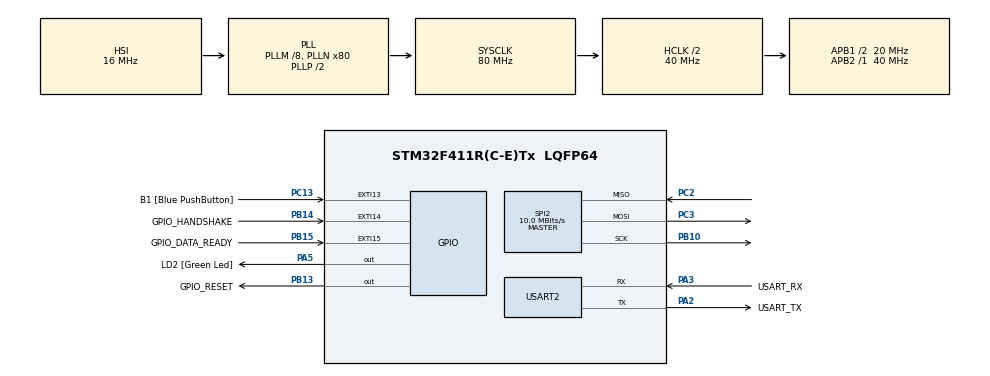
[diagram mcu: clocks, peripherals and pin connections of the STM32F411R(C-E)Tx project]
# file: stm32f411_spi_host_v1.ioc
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Dma.Request0=SPI2_RX
Dma.Request1=SPI2_TX
Dma.SPI2_RX.0.Direction=DMA_PERIPH_TO_MEMORY
Dma.SPI2_RX.0.FIFOMode=DMA_FIFOMODE_DISABLE
Dma.SPI2_RX.0.Instance=DMA1_Stream3
Dma.SPI2_RX.0.MemDataAlignment=DMA_MDATAALIGN_BYTE
Dma.SPI2_RX.0.MemInc=DMA_MINC_ENABLE
Dma.SPI2_RX.0.Mode=DMA_NORMAL
Dma.SPI2_RX.0.PeriphDataAlignment=DMA_PDATAALIGN_BYTE
Dma.SPI2_RX.0.PeriphInc=DMA_PINC_DISABLE
Dma.SPI2_RX.0.Priority=DMA_PRIORITY_LOW
Dma.SPI2_TX.1.Direction=DMA_MEMORY_TO_PERIPH
Dma.SPI2_TX.1.FIFOMode=DMA_FIFOMODE_DISABLE
Dma.SPI2_TX.1.Instance=DMA1_Stream4
Dma.SPI2_TX.1.MemDataAlignment=DMA_MDATAALIGN_BYTE
Dma.SPI2_TX.1.MemInc=DMA_MINC_ENABLE
Dma.SPI2_TX.1.Mode=DMA_NORMAL
Dma.SPI2_TX.1.PeriphDataAlignment=DMA_PDATAALIGN_BYTE
Dma.SPI2_TX.1.PeriphInc=DMA_PINC_DISABLE
Dma.SPI2_TX.1.Priority=DMA_PRIORITY_LOW
FREERTOS.BinarySemaphores01=myBinarySem01,Dynamic,NULL,Available
FREERTOS.Tasks01=defaultTask,0,128,StartDefaultTask,Default,NULL,Dynamic,NULL,NULL
FREERTOS.configTOTAL_HEAP_SIZE=86016
FREERTOS.configUSE_TIMERS=1
Mcu.Family=STM32F4
Mcu.Name=STM32F411R(C-E)Tx
Mcu.Package=LQFP64
NVIC.DMA1_Stream3_IRQn=true\:5\:0\:false\:false\:true\:true\:false\:true\:true
NVIC.DMA1_Stream4_IRQn=true\:5\:0\:false\:false\:true\:true\:false\:true\:true
NVIC.EXTI15_10_IRQn=true\:15\:0\:true\:false\:true\:true\:true\:true\:true
NVIC.PriorityGroup=NVIC_PRIORITYGROUP_4
NVIC.SPI2_IRQn=true\:5\:0\:false\:false\:true\:true\:true\:true\:true
NVIC.TIM1_UP_TIM10_IRQn=true\:15\:0\:false\:false\:true\:false\:false\:true\:true
NVIC.TimeBase=TIM1_UP_TIM10_IRQn
NVIC.TimeBaseIP=TIM10
PA13.GPIO_Label=TMS
PA13.Mode=Serial_Wire
PA13.Signal=SYS_JTMS-SWDIO
PA14.GPIO_Label=TCK
PA14.Mode=Serial_Wire
PA14.Signal=SYS_JTCK-SWCLK
PA2.GPIO_Label=USART_TX
PA2.Mode=Asynchronous
PA2.Signal=USART2_TX
PA3.GPIO_Label=USART_RX
PA3.Mode=Asynchronous
PA3.Signal=USART2_RX
PA5.GPIO_Label=LD2 [Green Led]
PA5.Signal=GPIO_Output
PB10.Mode=Full_Duplex_Master
PB10.Signal=SPI2_SCK
PB13.GPIO_Label=GPIO_RESET
PB13.PinState=GPIO_PIN_SET
PB13.Signal=GPIO_Output
PB14.GPIO_Label=GPIO_HANDSHAKE
PB14.Signal=GPXTI14
PB15.GPIO_Label=GPIO_DATA_READY
PB15.Signal=GPXTI15
PB9.Signal=SPI2_NSS
PC13-ANTI_TAMP.GPIO_Label=B1 [Blue PushButton]
PC13-ANTI_TAMP.GPIO_ModeDefaultEXTI=GPIO_MODE_IT_FALLING
PC13-ANTI_TAMP.Signal=GPXTI13
PC14-OSC32_IN.Mode=LSE-External-Oscillator
PC14-OSC32_IN.Signal=RCC_OSC32_IN
PC15-OSC32_OUT.Mode=LSE-External-Oscillator
PC15-OSC32_OUT.Signal=RCC_OSC32_OUT
PC2.Mode=Full_Duplex_Master
PC2.Signal=SPI2_MISO
PC3.Mode=Full_Duplex_Master
PC3.Signal=SPI2_MOSI
PH0\ -\ OSC_IN.Mode=HSE-External-Clock-Source
PH0\ -\ OSC_IN.Signal=RCC_OSC_IN
PH1\ -\ OSC_OUT.Mode=HSE-External-Clock-Source
PH1\ -\ OSC_OUT.Signal=RCC_OSC_OUT
ProjectManager.HeapSize=0x200
ProjectManager.StackSize=0x400
ProjectManager.TargetToolchain=STM32CubeIDE
RCC.48MHZClocksFreq_Value=40000000
RCC.AHBCLKDivider=RCC_SYSCLK_DIV2
RCC.AHBFreq_Value=40000000
RCC.APB1CLKDivider=RCC_HCLK_DIV2
RCC.APB1Freq_Value=20000000
RCC.APB1TimFreq_Value=40000000
RCC.APB2Freq_Value=40000000
RCC.APB2TimFreq_Value=40000000
RCC.CortexFreq_Value=40000000
RCC.FLatency-AdvancedSettings=FLASH_LATENCY_1
RCC.HCLKFreq_Value=40000000
RCC.HSE_VALUE=8000000
RCC.HSI_VALUE=16000000
RCC.PLLM=8
RCC.PLLN=80
RCC.SYSCLKFreq_VALUE=80000000
RCC.SYSCLKSource=RCC_SYSCLKSOURCE_PLLCLK
RCC.VCOOutputFreq_Value=160000000
SPI2.CalculateBaudRate=10.0 MBits/s
SPI2.Direction=SPI_DIRECTION_2LINES
SPI2.Mode=SPI_MODE_MASTER
SPI2.VirtualType=VM_MASTER
USART2.VirtualMode=VM_ASYNC
VP_FREERTOS_VS_CMSIS_V1.Mode=CMSIS_V1
VP_SYS_VS_tim10.Mode=TIM10
board=NUCLEO-F411RE

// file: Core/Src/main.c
/* USER CODE BEGIN Header */
/**
  ******************************************************************************
  * @file           : main.c
  * @brief          : Main program body
  ******************************************************************************
  * @attention
  *
  * Copyright (c) 2025 STMicroelectronics.
  * All rights reserved.
  *
  * This software is licensed under terms that can be found in the LICENSE file
  * in the root directory of this software component.
  * If no LICENSE file comes with this software, it is provided AS-IS.
  *
  ******************************************************************************
  */
/* USER CODE END Header */
#include "main.h"
#include "cmsis_os.h"
#include "dma.h"
#include "spi.h"
#include "usart.h"
#include "gpio.h"

void SystemClock_Config(void);
void MX_FREERTOS_Init(void);

/* USER CODE BEGIN 0 */
int __io_putchar(int ch)
{
	/* Place your implementation of fputc here */
	/* e.g. write a character to the USART6 and
	 * Loop until the end of transmission */
	HAL_UART_Transmit(&huart2, (uint8_t *)&ch, 1, 0xFFFF);

	return ch;
}
/* USER CODE END 0 */

int main(void)
{

  /* MCU Configuration--------------------------------------------------------*/

  /* Reset of all peripherals, Initializes the Flash interface and the Systick. */
  HAL_Init();

  /* Configure the system clock */
  SystemClock_Config();

  /* Initialize all configured peripherals */
  MX_GPIO_Init();
  MX_DMA_Init();
  MX_USART2_UART_Init();
  MX_SPI2_Init();

  /* Call init function for freertos objects (in cmsis_os2.c) */
  MX_FREERTOS_Init();

  /* Start scheduler */
  osKernelStart();

  /* We should never get here as control is now taken by the scheduler */

  /* Infinite loop */
  while (1)
  {
  }
}

void SystemClock_Config(void)
{
  RCC_OscInitTypeDef RCC_OscInitStruct = {0};
  RCC_ClkInitTypeDef RCC_ClkInitStruct = {0};

  /** Configure the main internal regulator output voltage
  */
  __HAL_RCC_PWR_CLK_ENABLE();
  __HAL_PWR_VOLTAGESCALING_CONFIG(PWR_REGULATOR_VOLTAGE_SCALE1);

  /** Initializes the RCC Oscillators according to the specified parameters
  * in the RCC_OscInitTypeDef structure.
  */
  RCC_OscInitStruct.OscillatorType = RCC_OSCILLATORTYPE_HSI;
  RCC_OscInitStruct.HSIState = RCC_HSI_ON;
  RCC_OscInitStruct.HSICalibrationValue = RCC_HSICALIBRATION_DEFAULT;
  RCC_OscInitStruct.PLL.PLLState = RCC_PLL_ON;
  RCC_OscInitStruct.PLL.PLLSource = RCC_PLLSOURCE_HSI;
  RCC_OscInitStruct.PLL.PLLM = 8;
  RCC_OscInitStruct.PLL.PLLN = 80;
  RCC_OscInitStruct.PLL.PLLP = RCC_PLLP_DIV2;
  RCC_OscInitStruct.PLL.PLLQ = 4;
  if (HAL_RCC_OscConfig(&RCC_OscInitStruct) != HAL_OK)
  {
    Error_Handler();
  }

  /** Initializes the CPU, AHB and APB buses clocks
  */
  RCC_ClkInitStruct.ClockType = RCC_CLOCKTYPE_HCLK|RCC_CLOCKTYPE_SYSCLK
                              |RCC_CLOCKTYPE_PCLK1|RCC_CLOCKTYPE_PCLK2;
  RCC_ClkInitStruct.SYSCLKSource = RCC_SYSCLKSOURCE_PLLCLK;
  RCC_ClkInitStruct.AHBCLKDivider = RCC_SYSCLK_DIV2;
  RCC_ClkInitStruct.APB1CLKDivider = RCC_HCLK_DIV2;
  RCC_ClkInitStruct.APB2CLKDivider = RCC_HCLK_DIV1;

  if (HAL_RCC_ClockConfig(&RCC_ClkInitStruct, FLASH_LATENCY_1) != HAL_OK)
  {
    Error_Handler();
  }
}

void HAL_TIM_PeriodElapsedCallback(TIM_HandleTypeDef *htim)
{
  if (htim->Instance == TIM10)
  {
    HAL_IncTick();
  }
}

void Error_Handler(void)
{
  __disable_irq();
  while (1)
  {
  }
}
